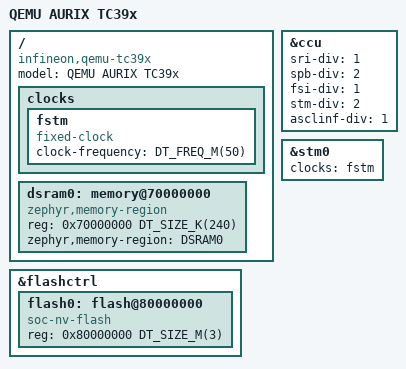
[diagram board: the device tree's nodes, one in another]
/*
 * SPDX-FileCopyrightText: Copyright (c) 2026 Infineon Technologies AG,
 * SPDX-FileCopyrightText: or an affiliate of Infineon Technologies AG. All rights reserved.
 * SPDX-FileCopyrightText: Copyright (c) 2026 Linumiz
 *
 * SPDX-License-Identifier: Apache-2.0
 */

#include <infineon/tc3x/tc3x.dtsi>

/ {
	model = "QEMU AURIX TC39x";
	compatible = "infineon,qemu-tc39x";

	clocks {
		fstm: fstm {
			compatible = "fixed-clock";
			clock-frequency = <DT_FREQ_M(50)>;
			#clock-cells = <0>;
		};
	};

	dsram0: memory@70000000 {
		compatible = "zephyr,memory-region", "mmio-sram";
		reg = <0x70000000 DT_SIZE_K(240)>;
		zephyr,memory-region = "DSRAM0";
	};
};

&flashctrl {
	flash0: flash@80000000 {
		compatible = "soc-nv-flash";
		reg = <0x80000000 DT_SIZE_M(3)>;
		ranges = <0x0 0x80000000 DT_SIZE_M(3)>;
		#address-cells = <1>;
		#size-cells = <1>;
	};
};

/* fsource0 = fBACK 100 MHz; dividers keep fSTM at 50 MHz */
&ccu {
	sri-div = <1>;
	spb-div = <2>;
	fsi-div = <1>;
	stm-div = <2>;
	asclinf-div = <1>;
};

/* The emulated STM runs at a fixed 50 MHz */
&stm0 {
	clocks = <&fstm>;
};
